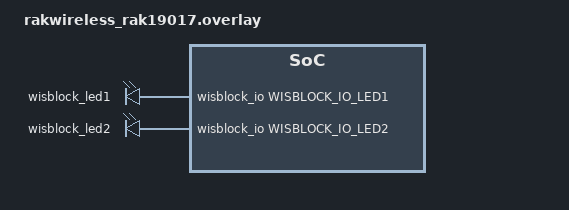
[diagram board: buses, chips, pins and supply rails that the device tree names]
/*
 * SPDX-License-Identifier: Apache-2.0
 * Copyright (c) 2026 RAKwireless Technology Limited
 */

#include <zephyr/dt-bindings/gpio/gpio.h>
#include <zephyr/dt-bindings/gpio/wisblock-io-slot.h>

/ {
	aliases {
		led0 = &wisblock_led1;
		led1 = &wisblock_led2;
	};

	leds {
		compatible = "gpio-leds";

		wisblock_led1: led0 {
			gpios = <&wisblock_io WISBLOCK_IO_LED1 GPIO_ACTIVE_HIGH>;
		};

		wisblock_led2: led1 {
			gpios = <&wisblock_io WISBLOCK_IO_LED2 GPIO_ACTIVE_HIGH>;
		};
	};
};
